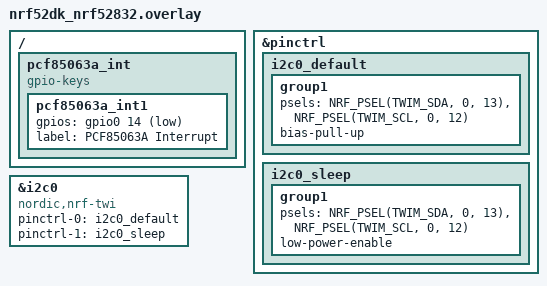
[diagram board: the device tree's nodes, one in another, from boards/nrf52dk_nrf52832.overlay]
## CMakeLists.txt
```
cmake_minimum_required(VERSION 3.20.0)
find_package(Zephyr REQUIRED HINTS $ENV{ZEPHYR_BASE})

project(PCF85063A)

# Always include PCF85063A.c
target_sources(app PRIVATE src/PCF85063A.c)

# Conditional compilation based on UNIT_TEST
if(UNIT_TEST)
    
    target_sources(app PRIVATE
        tests/test_pcf85063a.c
    )
    
    target_include_directories(app PRIVATE 
        ${CMAKE_CURRENT_SOURCE_DIR}/src
        ${ZEPHYR_BASE}/subsys/testsuite/include
        ${ZEPHYR_UNITY_MODULE_DIR}/src
    )
    
    # Explicitly exclude the original main.c to avoid double main definition as main is defined in Ztest
    set_source_files_properties(
        ${CMAKE_CURRENT_SOURCE_DIR}/src/main.c
        PROPERTIES
        EXCLUDE_FROM_ALL TRUE
    )
else()
    # Main application build
    target_sources(app PRIVATE src/main.c)
endif()

# Common Ztest configuration
if(CONFIG_ZTEST)
    target_include_directories(app PRIVATE 
        ${ZEPHYR_BASE}/subsys/testsuite/include
        ${ZEPHYR_UNITY_MODULE_DIR}/src
    )
endif()
```

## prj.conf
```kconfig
CONFIG_I2C=y
CONFIG_LOG=y
CONFIG_LOG_MODE_IMMEDIATE=y
CONFIG_LOG_DEFAULT_LEVEL=3
```

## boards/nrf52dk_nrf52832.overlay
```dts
&pinctrl {
    i2c0_default: i2c0_default {
        group1 {
            psels = <NRF_PSEL(TWIM_SDA, 0, 13)>,
                    <NRF_PSEL(TWIM_SCL, 0, 12)>;
                    bias-pull-up;
        };
    };

    i2c0_sleep: i2c0_sleep {
        group1 {
            psels = <NRF_PSEL(TWIM_SDA, 0, 13)>,
                    <NRF_PSEL(TWIM_SCL, 0, 12)>;
            low-power-enable;
        };
    };
};

arduino_i2c: &i2c0 {
    compatible = "nordic,nrf-twi";
    status = "okay";
    pinctrl-0 = <&i2c0_default>;
    pinctrl-1 = <&i2c0_sleep>;
    pinctrl-names = "default", "sleep";
};

/ {
    pcf85063a_int: pcf85063a_int {
        compatible = "gpio-keys";
        pcf85063a_int1: pcf85063a_int1 {
            gpios = <&gpio0 14 (GPIO_PULL_UP | GPIO_ACTIVE_LOW)>;
            label = "PCF85063A Interrupt";
        };
    };
};
```

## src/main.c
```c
#include <zephyr/kernel.h>
#include <zephyr/logging/log.h>
#include "PCF85063A.h"

LOG_MODULE_REGISTER(main, CONFIG_LOG_DEFAULT_LEVEL);

int main(void)
{
        uint8_t ret;
        uint8_t * time_array = get_civic_time();
        ret = initialize_RTC(time_array);
        if (ret != RTC_SUCCESS) {
                LOG_INF("RTC initialzation failed");
                return RTC_ERROR_DEVICE_SETUP;
        }
        else {
                LOG_INF("RTC initialized successfully");
        }
                 
        return RTC_SUCCESS;
}
```

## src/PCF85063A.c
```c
#include <zephyr/drivers/i2c.h>
#include <string.h>
#include <stdlib.h>
#include <zephyr/devicetree.h>
#include <zephyr/drivers/gpio.h>
#include <zephyr/kernel.h>
#include <zephyr/logging/log.h>
#include "PCF85063A.h"

LOG_MODULE_REGISTER(pcf85063a, CONFIG_PCF85063A_LOG_LEVEL);
static const struct device *pcf_85063A;
static const struct gpio_dt_spec int_gpio = GPIO_DT_SPEC_GET(PCF85063A_INT_NODE, gpios);
static struct gpio_callback gpio_cb;
static struct k_work alarm_work;
volatile bool alarm_trigger = false;

/**
 * @brief Extracts a time component from a string and converts it to BCD format
 *
 * This function takes a time string (typically in the format "HH:MM:SS")
 * and extracts a two-digit component starting at the specified index.
 * It then converts this component to Binary Coded Decimal (BCD) format.
 *
 * @param time_str Pointer to the time string
 * @param index Starting index of the time component to extract
 * @return uint8_t The extracted time component in BCD format
 */
uint8_t extract_time_component(const char *time_str, int index)
{
	return ((time_str[index] - '0') << BCD_SHIFT) | (time_str[index + 1] - '0');
}

/**
 * @brief Converts a decimal number to Binary Coded Decimal (BCD) format
 *
 * This function takes a decimal number (0-99) and converts it to BCD format.
 * In BCD, each decimal digit is encoded in four bits.
 *
 * @param decimal The decimal number to convert (0-99)
 * @return uint8_t The input number in BCD format
 */
uint8_t convert_to_bcd(uint8_t decimal)
{
	return ((decimal / 10) << BCD_SHIFT) | (decimal % 10);
}

/**
 * @brief Converts a month name to its corresponding number
 *
 * This function takes a three-letter month name (e.g., "Jan", "Feb")
 * and returns the corresponding month number (1-12).
 *
 * @param month_str Pointer to the month name string (3 characters)
 * @return uint8_t The month number (1-12), or 0 if the month is not recognized
 */
uint8_t find_month(const char *month_str)
{
	const char *months[] = {"Jan", "Feb", "Mar", "Apr", "May", "Jun",
				"Jul", "Aug", "Sep", "Oct", "Nov", "Dec"};
	for (int i = 0; i < 12; i++) {
		if (strcmp(month_str, months[i]) == 0) {
			return i + 1;
		}
	}
	return 0;
}

/**
 * @brief Returns the civic time in BCD format
 *
 * @return uint8_t* Pointer to an array containing:
 *         Sec, Min, Hr, day(1-31), Weekday, Month, Year
 * @note This is set at time of programming then maintained by RTC.
 *       If RTC power is lost make sure to rebuild and reprogram
 *       not just reprogram to maintain time.
 */
uint8_t *get_civic_time()
{
	const char *time_str = __TIME__;
	const char *date_str = __DATE__;
	static uint8_t time_array[7];

	// Extract month
	char month[DATE_MONTH_END + 1];
	strncpy(month, date_str, DATE_MONTH_END);
	month[DATE_MONTH_END] = '\0';
	uint8_t decimal_month = find_month(month);
	uint8_t bcd_month = convert_to_bcd(decimal_month);

	// Extract date
	char date[3];
	int j = DATE_DAY_START, k = 0;
	while (date_str[j] != ' ' && k < sizeof(date) - 1) {
		date[k++] = date_str[j++];
	}
	date[k] = '\0';
	uint8_t decimal_date = atoi(date);
	uint8_t bcd_date = convert_to_bcd(decimal_date);

	// Extract year
	char year[YEAR_DIGITS + 1];
	strncpy(year, &date_str[strlen(date_str) - YEAR_DIGITS], YEAR_DIGITS);
	year[YEAR_DIGITS] = '\0';
	uint8_t decimal_year = atoi(year);
	uint8_t bcd_year = convert_to_bcd(decimal_year);

	// Extract time
	uint8_t hours = extract_time_component(time_str, TIME_HOURS_INDEX);
	uint8_t minutes = extract_time_component(time_str, TIME_MINUTES_INDEX);
	uint8_t seconds = extract_time_component(time_str, TIME_SECONDS_INDEX);

	// Fill time array: sec, min, hr, day(1-31), weekday, month, year
	time_array[SECONDS_INDEX] = seconds;
	time_array[MINUTES_INDEX] = minutes;
	time_array[HOURS_INDEX] = hours;
	time_array[DATE_INDEX] = bcd_date;
	time_array[WEEKDAY_INDEX] = 0; // Weekday is not set
	time_array[MONTH_INDEX] = bcd_month;
	time_array[YEAR_INDEX] = bcd_year;

	return time_array;
}

/**
 * @brief Callback function for alarm interrupt
 *
 * @param dev Pointer to the device structure
 * @param cb Pointer to the GPIO callback structure
 * @param pins The pin mask for the callback
 */
static void alarm_callback(const struct device *dev, struct gpio_callback *cb, uint32_t pins)
{
	LOG_INF("Alarm triggered! \n");
	k_work_submit(&alarm_work);
}

/**
 * @brief Set the time for the RTC
 *
 * @param time_array Pointer to an array containing time in format:
 *                   sec, min, hr, day(1-31), weekday, month, year
 * @return rtc_error_t Status of initialization and write
 */
rtc_error_t initialize_RTC(const uint8_t *time_array)
{
	if (time_array == NULL) {
		LOG_ERR("Time array was null \n");
		return RTC_ERROR_INVALID_PARAMETER;
	}

	// Validate alarm time values
	if (time_array[SECONDS_INDEX] > 0x59 || time_array[MINUTES_INDEX] > 0x59 ||
	    time_array[HOURS_INDEX] > 0x23 || time_array[DATE_INDEX] > 0x31 ||
	    time_array[WEEKDAY_INDEX] != 0 || time_array[MONTH_INDEX] > 0x12 ||
	    time_array[YEAR_INDEX] == 0) {

		LOG_ERR("Invalid time array values \n");
		return RTC_ERROR_INVALID_PARAMETER;
	}

	pcf_85063A = DEVICE_DT_GET(DT_NODELABEL(i2c0));
	if (!device_is_ready(pcf_85063A)) {
		LOG_ERR("Error: i2c device is not ready\n");
		return RTC_ERROR_DEVICE_SETUP;
	}

	if (!device_is_ready(int_gpio.port)) {
		LOG_ERR("Error: interrupt GPIO device is not ready\n");
		return RTC_ERROR_DEVICE_SETUP;
	}

	int ret = gpio_pin_configure_dt(&int_gpio, GPIO_INPUT);
	if (ret != RTC_SUCCESS) {
		LOG_ERR("Error %d: failed to configure interrupt pin\n", ret);
		return RTC_ERROR_DEVICE_SETUP;
	}

	ret = gpio_pin_interrupt_configure_dt(&int_gpio, GPIO_INT_EDGE_TO_ACTIVE);
	if (ret != RTC_SUCCESS) {
		LOG_ERR("Error %d: failed to configure interrupt\n", ret);
		return RTC_ERROR_DEVICE_SETUP;
	}

	gpio_init_callback(&gpio_cb, alarm_callback, BIT(int_gpio.pin));
	gpio_add_callback(int_gpio.port, &gpio_cb);

	// Write the time array to the registers
	ret = i2c_burst_write(pcf_85063A, RTC_ADDRESS, RTC_TIME_REGISTER_ADDRESS, time_array,
			      RTC_TIME_REGISTER_SIZE);

	if (ret != RTC_SUCCESS) {
		LOG_ERR("Error %d: i2c burst write failed\n", ret);
		return RTC_ERROR_I2C_WRITE;
	}

	return RTC_SUCCESS;
}

/**
 * @brief Read from specified registers into provided read buffer
 *
 * @param read_buffer Pointer to the buffer to store read data
 * @param size Number of bytes to read
 * @param start_address Starting address to read from
 * @return rtc_error_t Read status code
 * @note Prints the result
 */
rtc_error_t read_register(uint8_t *read_buffer, const uint8_t size, const uint8_t start_address)
{
	// Input validation. Buffer is circular so reads beyond 18 are valid, but should not be
	// allowed for clarity.
	if (read_buffer == NULL) {
		LOG_ERR("read_buffer was null \n");
		return RTC_ERROR_INVALID_PARAMETER;
	}

	if (size <= 0 || size > RTC_REGISTER_SIZE) {
		LOG_ERR("Invalid size: %d, size must be between 0 and 18 \n", size);
		return RTC_ERROR_INVALID_PARAMETER;
	}

	if (start_address < 0 || start_address > RTC_REGISTER_SIZE) {
		LOG_ERR("Invalid start address: %d, start address must be between 0 and 17 \n",
			start_address);
		return RTC_ERROR_INVALID_PARAMETER;
	}

	if ((start_address + size) > RTC_REGISTER_SIZE) {
		LOG_ERR("Invalid read range, outranged RTC registers");
		return RTC_ERROR_INVALID_PARAMETER;
	}

	uint8_t ret = 0;
	ret = i2c_burst_read(pcf_85063A, RTC_ADDRESS, start_address, read_buffer, size);

	if (ret != RTC_SUCCESS) {
		LOG_ERR("Error %d: burst read failed \n", ret);
		return RTC_ERROR_I2C_WRITE;
	}

	for (int i = 0; i < size; i++) {
		LOG_INF("Register[%d]: %02X \n", i, read_buffer[i]);
	}

	return RTC_SUCCESS;
}

/**
 * @brief Write to specified registers from provided write buffer
 *
 * @param write_buffer Pointer to the buffer containing data to write
 * @param size Number of bytes to write
 * @param start_address Starting address to write to
 * @return rtc_error_t Write status code
 */
rtc_error_t write_register(const uint8_t *write_buffer, const uint8_t size,
			   const uint8_t start_address)
{
	// Input validation. Buffer is circular so writes beyond 18 are valid, but should not be
	// allowed for clarity.
	if (write_buffer == NULL) {
		LOG_ERR("Write buffer was null \n");
		return RTC_ERROR_INVALID_PARAMETER;
	}

	if (size <= 0 || size > RTC_REGISTER_SIZE) {
		LOG_ERR("Invalid size: %d, size must be between 0 and 18 \n", size);
		return RTC_ERROR_INVALID_PARAMETER;
	}

	if (start_address < 0 || start_address > RTC_REGISTER_SIZE) {
		LOG_ERR("Invalid start address: %d, start address must be between 0 and 17 \n",
			start_address);
		return RTC_ERROR_INVALID_PARAMETER;
	}

	if ((start_address + size) > RTC_REGISTER_SIZE) {
		LOG_ERR("Invalid write range, outranged RTC registers \n");
		return RTC_ERROR_INVALID_PARAMETER;
	}

	uint8_t ret = 0;
	ret = i2c_burst_write(pcf_85063A, RTC_ADDRESS, start_address, write_buffer, size);

	if (ret != RTC_SUCCESS) {
		LOG_ERR("Error %d: burst write failed \n", ret);
		return RTC_ERROR_I2C_WRITE;
	}

	return RTC_SUCCESS;
}

/**
 * @brief Placeholder function, currently reads all registers when alarm is called
 * and sets alarm_trigger to true for validation in testing
 *
 * @param work Pointer to the work structure
 */
static void alarm_work_handler(struct k_work *work)
{
	uint8_t read_buffer[RTC_REGISTER_SIZE] = {0};
	read_register(read_buffer, RTC_REGISTER_SIZE, 0X00);
	alarm_trigger = true;
}

/**
 * @brief Set the alarm with a given time in BCD format
 *
 * @param alarm_buffer Pointer to an array containing:
 *                     Sec, min, hour, day, weekday
 * @param size Size of the alarm_buffer
 * @return rtc_error_t Status of the alarm setting operation
 * @note Triggers interrupt work function when time is reached
 */
rtc_error_t set_alarm(const uint8_t *alarm_buffer, const size_t size)
{
	// Input validation
	if (alarm_buffer == NULL) {
		LOG_ERR("Alarm buffer is NULL \n");
		return RTC_ERROR_INVALID_PARAMETER;
	}

	if (size != RTC_ALARM_REGISTER_SIZE) {
		LOG_ERR("Invalid alarm buffer size. Expected %d, got %d \n",
			RTC_ALARM_REGISTER_SIZE, size);
		return RTC_ERROR_INVALID_PARAMETER;
	}

	// Validate alarm time values
	if (alarm_buffer[SECONDS_INDEX] > 0x59 || alarm_buffer[MINUTES_INDEX] > 0x59 ||
	    alarm_buffer[HOURS_INDEX] > 0x23 || alarm_buffer[DATE_INDEX] > 0x31 ||
	    alarm_buffer[WEEKDAY_INDEX] != 0) {
		LOG_ERR("Invalid alarm time values \n");
		return RTC_ERROR_INVALID_PARAMETER;
	}

	// Set the control register
	uint8_t control_2[ALARM_CONTROL_REGISTER], ret = 0;
	control_2[0] = ENABLE_ALARM;
	ret = write_register(control_2, sizeof(control_2), ALARM_CONTROL_REGISTER);
	if (ret != RTC_SUCCESS) {
		LOG_ERR("Error: %d. Failed to set alarm control register due to burst write "
			"failure \n",
			ret);
		return RTC_ERROR_I2C_WRITE;
	}

	// Set the alarm register
	ret = write_register(alarm_buffer, size, RTC_ALARM_REGISTER_ADDRESS);
	if (ret != RTC_SUCCESS) {
		LOG_ERR("Error: %d. Failed to set alarm time register due to burst write failure "
			"\n",
			ret);
		return RTC_ERROR_I2C_WRITE;
	}
	k_work_init(&alarm_work, alarm_work_handler);
	return RTC_SUCCESS;
}
```

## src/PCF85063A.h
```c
#ifndef PCF85063_H
#define PCF85063_H

#define SECONDS_INDEX 0
#define MINUTES_INDEX 1
#define HOURS_INDEX 2
#define DATE_INDEX 3
#define WEEKDAY_INDEX 4
#define MONTH_INDEX 5
#define YEAR_INDEX 6
#define TIME_HOURS_INDEX 0
#define TIME_MINUTES_INDEX 3
#define TIME_SECONDS_INDEX 6
#define DATE_MONTH_END 3
#define DATE_DAY_START 4
#define YEAR_DIGITS 2
#define BCD_SHIFT 4
#define CONFIG_PCF85063A_LOG_LEVEL 3

#define RTC_ADDRESS 0x51
#define RTC_REGISTER_SIZE 18
#define RTC_ALARM_REGISTER_SIZE 5
#define RTC_TIME_REGISTER_ADDRESS 0x04
#define RTC_ALARM_REGISTER_ADDRESS 0x0B
#define RTC_TIME_REGISTER_SIZE 7
#define ENABLE_ALARM 0x80
#define ALARM_CONTROL_REGISTER 1

#define PCF85063A_INT_NODE DT_NODELABEL(pcf85063a_int1)

typedef enum {
    RTC_SUCCESS = 0,
    RTC_ERROR_DEVICE_SETUP = -1,
    RTC_ERROR_I2C_WRITE = -2,
    RTC_ERROR_I2C_READ = -3,
    RTC_ERROR_INVALID_PARAMETER = -4,
    RTC_ERROR_GPIO_CONFIG = -5,
} rtc_error_t;

extern volatile bool alarm_trigger;

uint8_t * get_civic_time();
uint8_t extract_time_component(const char *time_str, int index);
uint8_t find_month(const char *month_str);
uint8_t find_month(const char *month_str);

rtc_error_t initialize_RTC(const uint8_t *time_array);
rtc_error_t read_register(uint8_t *read_buffer, const uint8_t size, const uint8_t start_address);
rtc_error_t write_register(const uint8_t *write_buffer, const uint8_t size, const uint8_t start_address);

rtc_error_t set_alarm(const uint8_t *alarm_buffer, const size_t size);



#endif
```
